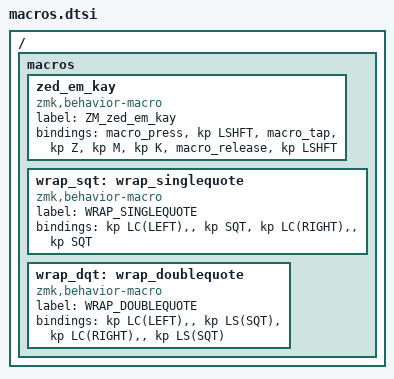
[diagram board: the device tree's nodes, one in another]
/ {
    macros {
        zed_em_kay: zed_em_kay {
            label = "ZM_zed_em_kay";
            compatible = "zmk,behavior-macro";
            #binding-cells = <0>;
            bindings
                = <&macro_press &kp LSHFT>
                , <&macro_tap &kp Z &kp M &kp K>
                , <&macro_release &kp LSHFT>
                ;
        };

        wrap_sqt: wrap_singlequote {
            label = "WRAP_SINGLEQUOTE";
            compatible = "zmk,behavior-macro";
            #binding-cells = <0>;
            bindings
                = <&kp LC(LEFT), &kp SQT>
				, <&kp LC(RIGHT), &kp SQT>
                ;
        };

        wrap_dqt: wrap_doublequote {
            label = "WRAP_DOUBLEQUOTE";
            compatible = "zmk,behavior-macro";
            #binding-cells = <0>;
            bindings
                = <&kp LC(LEFT), &kp LS(SQT)>
				, <&kp LC(RIGHT), &kp LS(SQT)>
                ;
        };
    };
};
